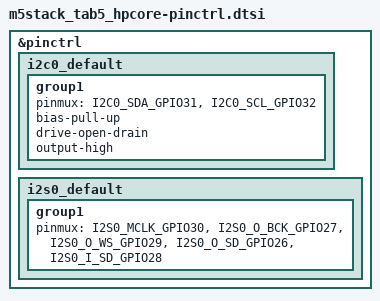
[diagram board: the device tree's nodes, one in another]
/*
 * SPDX-FileCopyrightText: Copyright The Zephyr Project Contributors
 * SPDX-License-Identifier: Apache-2.0
 */

#include <zephyr/dt-bindings/pinctrl/esp-pinctrl-common.h>
#include <zephyr/dt-bindings/pinctrl/esp32p4-pinctrl.h>
#include <zephyr/dt-bindings/pinctrl/esp32p4-gpio-sigmap.h>

&pinctrl {
	i2c0_default: i2c0_default {
		group1 {
			pinmux = <I2C0_SDA_GPIO31>,
				 <I2C0_SCL_GPIO32>;
			bias-pull-up;
			drive-open-drain;
			output-high;
		};
	};

	i2s0_default: i2s0_default {
		group1 {
			pinmux = <I2S0_MCLK_GPIO30>,
				 <I2S0_O_BCK_GPIO27>,
				 <I2S0_O_WS_GPIO29>,
				 <I2S0_O_SD_GPIO26>,
				 <I2S0_I_SD_GPIO28>;
		};
	};
};
